# USBPHY register map
Vendor: Texas Instruments
Peripheral module from a debugger description file (folder omap4460).
Registers are 32-bit, access per field, reset 0x0 unless marked. A register's access mark holds for its fields unless they carry their own. Offsets are as the file gives them; lines under a group give offsets from that group; [hi:lo] are bit positions; {n}, {i} and the like mark numbered series; 'fields as' and 'values as' point back to an identical list; <NAME> marks a mode.

## USBPHY
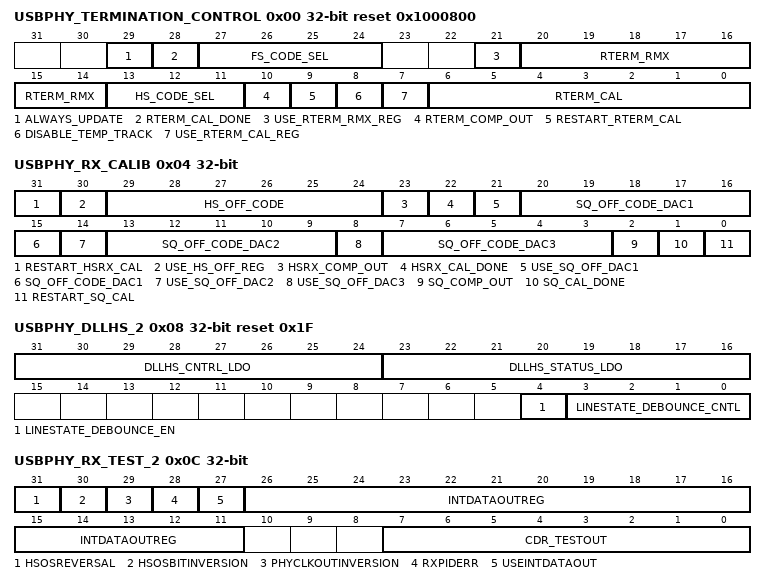
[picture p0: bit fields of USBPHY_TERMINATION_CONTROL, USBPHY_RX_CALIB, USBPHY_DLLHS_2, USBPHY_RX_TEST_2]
0x00 USBPHY_TERMINATION_CONTROL reset 0x1000800 — Contains bits related to control of terminations in USBPHY
  [29] ALWAYS_UPDATE rw — When set to 1, the calibration code is updated immediately after a code computation without waiting for idle periods.
  [28] RTERM_CAL_DONE ro — Rterm calibration is done. First time cal is done this bit gets set and gets reset at a restart cal. Read value is valid only if VDDLDO is on.
  [27:24] FS_CODE_SEL rw — FS Code selection control
  [21] USE_RTERM_RMX_REG rw — Override termination resistor trim code with RTERM_RMX from this register
  [20:14] RTERM_RMX rw — When read, this field returns the current Termination resistor trim code. Read value is valid only if VDDLDO is on. The value written to this field is used as Termination resistor trim code if bit 21 is set to 1
  [13:11] HS_CODE_SEL rw — HS Code selection control. A higher positive value (for example, +3 -- 011) reduces the termination resistance and improves the vertical eye opening.HS_CODE_SEL Offset Value Termination Calibrated Value . 000 0 ~1.5% . 001 +1 (default) 0% . 010 +2 ~–1.5% . 011 +3 ~–3% . 100 –1 3% . 101 –2 4.5% . 110 –3 6% . 111 –4 7.5% .
  [10] RTERM_COMP_OUT ro — Master loop comparator output. Read value is valid only if VDDLDO is on.
  [9] RESTART_RTERM_CAL rw — Restart the rterm calibration. the calibration restarts on any toggle 0-1 or 1-0 on this bit.
  [8] DISABLE_TEMP_TRACK rw — Disables the temperature tracking function of the termination calibration
  [7] USE_RTERM_CAL_REG rw — When 1, the rterm cal code is overridden by values in RTERM_CAL
  [6:0] RTERM_CAL rw — When read this field returns the current rterm calibration code. Read value is valid only if VDDLDO is on. The value written to this filed is used as rterm calibration code if the bit USE_RTERM_CAL_REG is 1.
0x04 USBPHY_RX_CALIB — Contains bits related to RX calibration
  [31] RESTART_HSRX_CAL rw — Restart the HSRX calibration state machine when this bit goes from 0 to 1.
  [30] USE_HS_OFF_REG rw — Override HS offset correction with HS_OFF_CODE when set to 1
  [29:24] HS_OFF_CODE rw — HS offset code, this code is forced when bit 30 is 1. Code is updated from calibration logic when bit 30 = 0.
  [23] HSRX_COMP_OUT ro — The output of the HSRX comparator. Read value is valid only if VDDLDO is on.
  [22] HSRX_CAL_DONE ro — Signal that indicates that the HSRX calibration is done. This gets reset at every restart. Read value is valid only if VDDLDO is on.
  [21] USE_SQ_OFF_DAC1 rw — Override Squelch offset DAC1 code when '1'
  [20:15] SQ_OFF_CODE_DAC1 rw — When read returns current Sq offset code for DAC1, if VDDLDO is on. When written this is used as Sq offset code for DAC1 when USE_SQ_OFF_DAC1 = 1
  [14] USE_SQ_OFF_DAC2 rw — Override Squelch offset DAC2 code when '1'
  [13:9] SQ_OFF_CODE_DAC2 rw — When read returns current Sq offset code for DAC2, if VDDLDO is on. When written this is used as Sq offset code for DAC2 when USE_SQ_OFF_DAC2 = 1
  [8] USE_SQ_OFF_DAC3 rw — Override Squelch offset DAC3 code when 1
  [7:3] SQ_OFF_CODE_DAC3 rw — When read returns current Sq offset code for DAC3, if VDDLDO is on. When written this is used as Sq offset code for DAC3 when USE_SQ_OFF_DAC3 = 1
  [2] SQ_COMP_OUT ro — Sq comp output.Read value is valid only if VDDLDO is on.
  [1] SQ_CAL_DONE ro — Sq calibration is done when this bit = 1. See RESTART_SQ_CAL for more description. Read value is valid only if VDDLDO is on.
  [0] RESTART_SQ_CAL rw — The squelch calibration continuously goes through restart cycles when this bit is 1.
0x08 USBPHY_DLLHS_2 reset 0x1F — Second DLLHS control register. Bits 4:0 are unrelated to the DLLHS and are linestate filter settings.
  [31:24] DLLHS_CNTRL_LDO rw
  [23:16] DLLHS_STATUS_LDO ro
  [4] LINESTATE_DEBOUNCE_EN rw — Enables the linestate debounce filter
  [3:0] LINESTATE_DEBOUNCE_CNTL rw — Used for control of the linestate debounce filter when going from syncronous to async linestate.
0x0C USBPHY_RX_TEST_2 — Second receiver test register
  [31] HSOSREVERSAL rw — Swaps the dataout from HSOS
  [30] HSOSBITINVERSION rw — Inverts the HSOS bits
  [29] PHYCLKOUTINVERSION rw — This inverts the phase for the PHYCLKOUT
  [28] RXPIDERR ro — Flags if the RX data packet has PID error. NOT IMPLEMENTED.
  [27] USEINTDATAOUT rw — This will bypass the analog and will send data packet to controller incase of receiver (Faking the receive data). data used will be INTDATAOUTREG
  [26:11] INTDATAOUTREG rw — This register will be loaded through OCP and this data will be given to the controller if USEINTDATAOUT is set to 1
  [7:0] CDR_TESTOUT ro — CDR debug bits. Read value is valid only if VDDLDO is on.
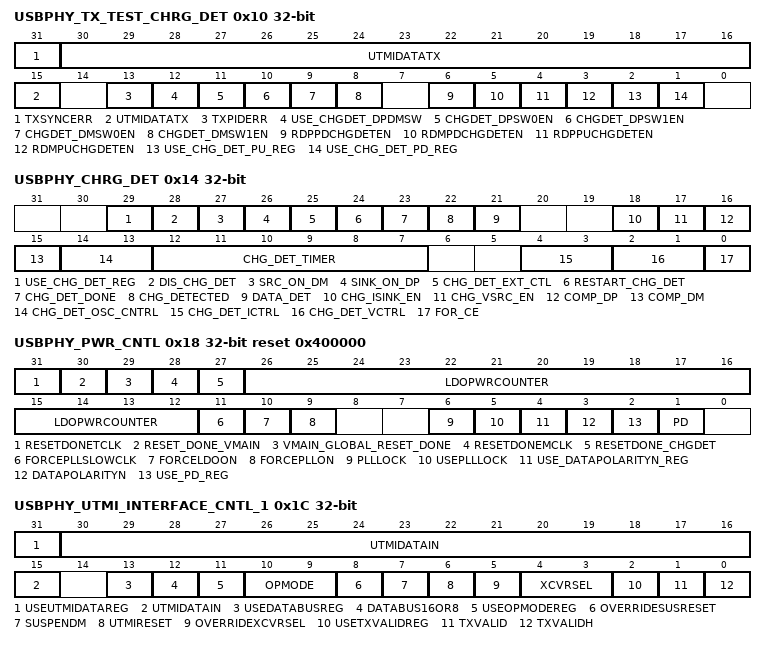
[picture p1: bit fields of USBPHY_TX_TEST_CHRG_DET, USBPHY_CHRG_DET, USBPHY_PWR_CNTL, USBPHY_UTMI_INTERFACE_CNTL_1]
0x10 USBPHY_TX_TEST_CHRG_DET — TX test register and also charger detect register
  [31] TXSYNCERR ro — Sync error on TX data. NOT IMPLEMENTED.
  [30:15] UTMIDATATX ro — Stores Last 2 byte of transmit data coming from the controller. NOT IMPLEMENTED .
  [13] TXPIDERR ro — Flags if the TX packet has PID error. NOT IMPLEMENTED.
  [12] USE_CHGDET_DPDMSW rw — Use bits 11:8 as override bits
  [11] CHGDET_DPSW0EN rw — Overrides the same named A/D interface signal for the charger detect block
  [10] CHGDET_DPSW1EN rw — Overrides the same named A/D interface signal for the charger detect block. Read value is valid only if VCHGLDO is on.
  [9] CHGDET_DMSW0EN rw — Overrides the same named A/D interface signal for the charger detect block. Read value is valid only if VCHGLDO is on.
  [8] CHGDET_DMSW1EN rw — Overrides the same named A/D interface signal for the charger detect block..Read value is valid only if VCHGLDO is on.
  [6] RDPPDCHGDETEN rw — When set to 1 connects a 15K (+/- 30%) pulldown resistor on DP. Read value is valid only if VCHGLDO is on.
  [5] RDMPDCHGDETEN rw — When set to 1 connects a 15K (+/- 30%) pulldown resistor on DM. Read value is valid only if VCHGLDO is on.
  [4] RDPPUCHGDETEN rw — When set to 1 connects a 150K (+/- 30%) pullup resistor on DP. Read value is valid only if VCHGLDO is on.
  [3] RDMPUCHGDETEN rw — When set to 1 connects a 150K (+/- 30%) pullup resistor on DM. Read value is valid only if VCHGLDO is on.
  [2] USE_CHG_DET_PU_REG rw — Use bits 4:3 from this register
  [1] USE_CHG_DET_PD_REG rw — Use bits 6:5 from this register.
0x14 USBPHY_CHRG_DET — This is the charger detect register. This register is not used in the dead battery case.
  [29] USE_CHG_DET_REG rw — Use bits 28:24 and 18:17 from this register
  [28] DIS_CHG_DET rw — When read, returns current value of charger detect input. When USE_CHG_DET_REG = 1, the value written to this filed overrides the corresponding charger detect input.
  [27] SRC_ON_DM rw — When read, returns current value of charger detect input. When USE_CHG_DET_REG = 1, the value written to this filed overrides the corresponding charger detect input.
  [26] SINK_ON_DP rw — When read, returns current value of charger detect input. When USE_CHG_DET_REG = 1, the value written to this filed overrides the corresponding charger detect input.
  [25] CHG_DET_EXT_CTL rw — When read, returns current value of charger detect input. When USE_CHG_DET_REG = 1, the value written to this filed overrides the corresponding charger detect input.
  [24] RESTART_CHG_DET rw — Restart the charger detection protocol when this goes from 0 to 1
  [23] CHG_DET_DONE ro — Charger detect protocol has completed
  [22] CHG_DETECTED ro — Same signal as CE pin
  [21] DATA_DET ro — Output of the data det comparator
  [18] CHG_ISINK_EN rw — When read, returns current value of charger detect input. When USE_CHG_DET_REG = 1, the value written to this filed overrides the corresponding charger detect input.
  [17] CHG_VSRC_EN rw — When read, returns current value of charger detect input. When USE_CHG_DET_REG = 1, the value written to this filed overrides the corresponding charger detect input.
  [16] COMP_DP ro — Comparator on the DP line value
  [15] COMP_DM ro — Comparator on the DM line value
  [14:13] CHG_DET_OSC_CNTRL rw — Charger detect osc control
  [12:7] CHG_DET_TIMER rw — Charger detect timer control.
  [4:3] CHG_DET_ICTRL rw — Charger detect current control
  [2:1] CHG_DET_VCTRL rw — Charger detect voltage buffer control
  [0] FOR_CE rw — Force CE = 1 when this bit is set
0x18 USBPHY_PWR_CNTL reset 0x400000 — Includes all the power control bits
  [31] RESETDONETCLK ro — Goes high when the RESET is synchronized to TCLK
  [30] RESET_DONE_VMAIN ro — Goes high when LDO domain is up, PLL LOCK is available, and utmi_reset is deasserted.
  [29] VMAIN_GLOBAL_RESET_DONE ro — Goes high when LDO domain is up and PLL LOCK is available.
  [28] RESETDONEMCLK ro — Goes high when the RESET is synchronized to MCLK
  [27] RESETDONE_CHGDET ro — Goes high when the RESET is synchronized to charger detect oscillator clock domain
  [26:12] LDOPWRCOUNTER rw — This is the value of the counter used for LDO power up. RESET to default.
  [11] FORCEPLLSLOWCLK rw — Forces the PLL to the slow clk mode
  [10] FORCELDOON rw — Forces the LDO to be ON.
  [9] FORCEPLLON rw — Forces the PLL to be ON.
  [6] PLLLOCK ro — Lock signal from the PLL
  [5] USEPLLLOCK rw — This signal is used to indicate to the Phy, not to do any clock related activity until PLLLOCK = 1.This is not the default option. 0 - do not use PLLLOCK. 1 - use PLLLOCK as a clock gate.
  [4] USE_DATAPOLARITYN_REG rw — 1 - use bit 3 as override for the DATAPOLARITYN signal.
  [3] DATAPOLARITYN rw — Override value of datapolarityn
  [2] USE_PD_REG rw — Use bit 1 from this register as PD override when set to 1
  [1] PD rw — Override value for PD
0x1C USBPHY_UTMI_INTERFACE_CNTL_1 rw — register to override UTMI interface control pins.
  [31] USEUTMIDATAREG — Use datain from UTMI interface register
  [30:15] UTMIDATAIN — Override value for the UTMIDATAIN
  [13] USEDATABUSREG — When set to 1 use bit 12 from register instead of interface
  [12] DATABUS16OR8 — Override value for UTMI signal DATABUS16OR8
  [11] USEOPMODEREG — When set to 1 use bits 10:9 from register instead of interface
  [10:9] OPMODE — Override value for UTMI signal OPMODE[1:0]
  [8] OVERRIDESUSRESET — Override the suspend and reset values. Use bits 6 and 7
  [7] SUSPENDM — Override value for UTMI signal SUSPENDM
  [6] UTMIRESET — Override value for UTMI signal UTMIRESET
  [5] OVERRIDEXCVRSEL — When set to 1 use bits 4:3 from register instead of interface
  [4:3] XCVRSEL — Override value for UTMI signal XCVRSEL[1:0]
  [2] USETXVALIDREG — When set to 1 use bits 1:0 from register instead of interface
  [1] TXVALID — Override value for UTMI signal TXVALID
  [0] TXVALIDH — Override value for UTMI signal TXVALIDH
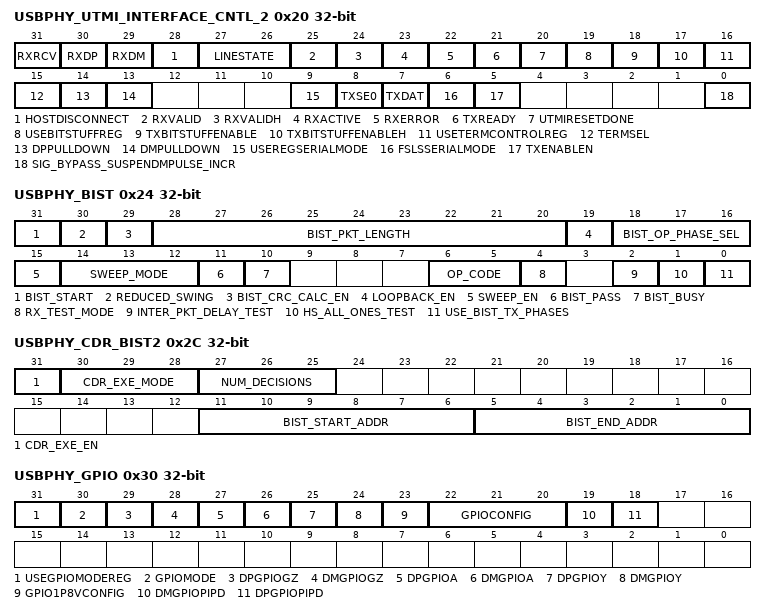
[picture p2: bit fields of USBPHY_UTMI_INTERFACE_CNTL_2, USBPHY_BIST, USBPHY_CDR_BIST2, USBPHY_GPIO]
0x20 USBPHY_UTMI_INTERFACE_CNTL_2 — UTMI interface override and observe register 2
  [31] RXRCV ro — Read for UTMI signal. Read value is valid only if VDDLDO is on. Read value is valid only if VDDLDO is on.
  [30] RXDP ro — Read for UTMI signal. Read value is valid only if VDDLDO is on.
  [29] RXDM ro — Read for UTMI signal. Read value is valid only if VDDLDO is on.
  [28] HOSTDISCONNECT ro — Read for UTMI signal. Read value is valid only if VDDLDO is on.
  [27:26] LINESTATE ro — Read for UTMI signal. Read value is valid only if VDDLDO is on.
  [25] RXVALID ro — Read for UTMI signal. Read value is valid only if VDDLDO is on.
  [24] RXVALIDH ro — Read for UTMI signal. Read value is valid only if VDDLDO is on.
  [23] RXACTIVE ro — Read for UTMI signal. Read value is valid only if VDDLDO is on.
  [22] RXERROR ro — Read for UTMI signal. Read value is valid only if VDDLDO is on.
  [21] TXREADY ro — Read for UTMI signal. Read value is valid only if VDDLDO is on.
  [20] UTMIRESETDONE ro — Read for UTMIRESETDONE signal
  [19] USEBITSTUFFREG rw — When set to 1 use bits 18-17 from register instead of interface
  [18] TXBITSTUFFENABLE rw — Override value for signal TXBITSTUFFENABLE
  [17] TXBITSTUFFENABLEH rw — Override value for pin TXBITSTUFFENABLE
  [16] USETERMCONTROLREG rw — When set to 1, bits 15:13 from register are used instead of interface
  [15] TERMSEL rw — Override value for signal TERMSEL
  [14] DPPULLDOWN rw — Override value for signal DPPULLDOWN
  [13] DMPULLDOWN rw — Override value for signal DMPULLDOWN
  [9] USEREGSERIALMODE rw — When set to 1 use bits 8:5 from register instead of interface
  [8] TXSE0 rw — Override value for signal TXSE0
  [7] TXDAT rw — Override value for signal TXDAT
  [6] FSLSSERIALMODE rw — Override value for signal FSLSSERIALMODE
  [5] TXENABLEN rw — Override value for signal TXENABLEN
  [0] SIG_BYPASS_SUSPENDMPULSE_INCR rw — If the suspend signal is asserted for a short time, it is pulse-extended so that the sampling logic samples it reliably.
    0=Pulse extension active; 1=Bypass pulse extension
0x24 USBPHY_BIST — COntains bits related to the built in self test of the phy
  [31] BIST_START rw — When set to 1 the BIST mode is started.
  [30] REDUCED_SWING rw — When 1 the TX swing is reduced in BIST mode
  [29] BIST_CRC_CALC_EN rw — Enables CRC calculation during BIST when set to 1
  [28:20] BIST_PKT_LENGTH rw — Address for which BIST to select
  [19] LOOPBACK_EN rw — Enables the loopback mode
  [18:16] BIST_OP_PHASE_SEL rw — Selects which phase to use for data transmission during BIST
  [15] SWEEP_EN rw — Enables freq sweep on CDR
  [14:12] SWEEP_MODE rw — Selects the freq sweep mode.
  [11] BIST_PASS ro — Indicates that the BIST has passed. Read value is valid only if VDDLDO is on.
  [10] BIST_BUSY ro — Indicates that BIST is running. Read value is valid only if VDDLDO is on.
  [6:5] OP_CODE rw
  [4] RX_TEST_MODE rw
  [2] INTER_PKT_DELAY_TEST rw
  [1] HS_ALL_ONES_TEST rw
  [0] USE_BIST_TX_PHASES rw — When set to 1 bits 18:16 are activated for choosing the transmitting phase.
0x28 USBPHY_BIST_CRC rw — CRC code for BIST test
  [31:0] BIST_CRC — The CRC value from the BIST.
0x2C USBPHY_CDR_BIST2 — clock data recovery register and BIST register 2
  [31] CDR_EXE_EN rw — CDR debug bits
  [30:28] CDR_EXE_MODE rw — CDR debug bits
  [27:25] NUM_DECISIONS rw — CDR debug bits
  [11:6] BIST_START_ADDR rw
  [5:0] BIST_END_ADDR rw
0x30 USBPHY_GPIO — GPIO mode configurations and reads
  [31] USEGPIOMODEREG rw — When set to 1 use bits 31:24 from this register instead of primary inputs
  [30] GPIOMODE rw — Overrides the corresponding primary input
  [29] DPGPIOGZ rw — Overrides the corresponding primary input
  [28] DMGPIOGZ rw — Overrides the corresponding primary input
  [27] DPGPIOA rw — Overrides the corresponding primary input
  [26] DMGPIOA rw — Overrides the corresponding primary input
  [25] DPGPIOY ro — The GPIO Y output is stored here
  [24] DMGPIOY ro — The GPIO Y output is stored here
  [23] GPIO1P8VCONFIG rw — Overrides the corresponding primary input
  [22:20] GPIOCONFIG rw — Used for configuring the GPIOs.
  [19] DMGPIOPIPD rw — GPIO mode DM pull-down enabled. Overrides the corresponding primary input
  [18] DPGPIOPIPD rw — GPIO mode DP pull-down enabled. Overrides the corresponding primary input.
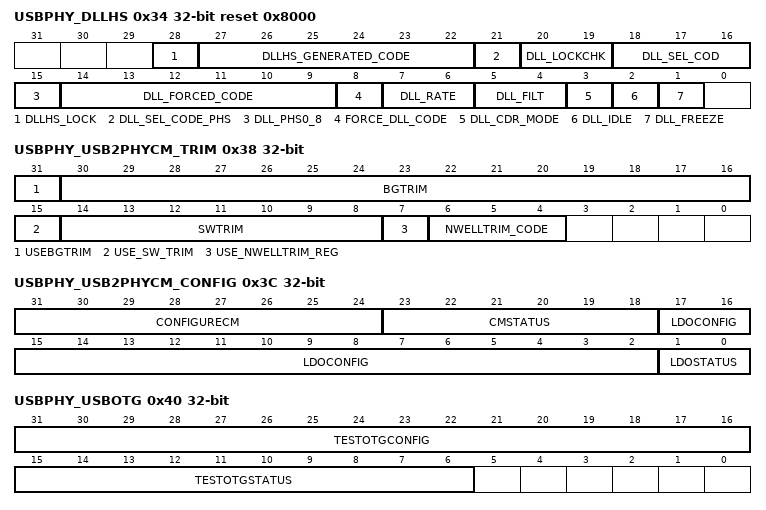
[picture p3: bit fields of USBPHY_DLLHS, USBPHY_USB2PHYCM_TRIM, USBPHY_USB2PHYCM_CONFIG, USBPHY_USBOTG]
0x34 USBPHY_DLLHS reset 0x8000 — Bits for control and debug of the DLL inside the USBPHY
  [28] DLLHS_LOCK ro — Read the AFE output by this name
  [27:22] DLLHS_GENERATED_CODE ro — Read the AFE output by this name.Read value is valid only if VDDLDO is on.
  [21] DLL_SEL_CODE_PHS rw — Connect to DLLHS_TEST_LDO[0] on AFE interface.
  [20:19] DLL_LOCKCHK rw — Connect to DLLHS_TEST_LDO[2:1] on AFE interface.
  [18:16] DLL_SEL_COD rw — Connect to DLLHS_TEST_LDO[5:3] on AFE interface.
  [15] DLL_PHS0_8 rw — Connect to DLLHS_TEST_LDO[6] on AFE interface.
  [14:9] DLL_FORCED_CODE rw — Connect to the pin of this name on AFE interface.
  [8] FORCE_DLL_CODE rw — Connect to DLLHS_TEST_LDO[11] on AFE interface.
  [7:6] DLL_RATE rw — Connect to DLLHS_TEST_LDO[8:7] on AFE interface.
  [5:4] DLL_FILT rw — Connect to DLLHS_TEST_LDO[10:9] on AFE interface.
  [3] DLL_CDR_MODE rw — Connect to the pin of this name on AFE interface.
  [2] DLL_IDLE rw — Connect to DLLHS_TEST_LDO[12] on AFE interface.
  [1] DLL_FREEZE rw — Connect to DLLHS_TEST_LDO[13] on AFE interface.
0x38 USBPHY_USB2PHYCM_TRIM rw — Contains trim bit overrides for the USBPHYCM
  [31] USEBGTRIM — When set to 1 bits 30:16 are used as the trim value for the USBPHYCM bandgap
  [30:16] BGTRIM — Override value for the BGTRIM value
  [15] USE_SW_TRIM — Use bits 14:8 to override the switch cap trim value.
  [14:8] SWTRIM — Override value for the switch cap trim value.
  [7] USE_NWELLTRIM_REG — Override NWELL resistor trim using NWELLTRIM_CODE
  [6:4] NWELLTRIM_CODE — NWELL resistor trim code.
0x3C USBPHY_USB2PHYCM_CONFIG — Configuration and status register for the USBPHYCM and LDO
  [31:24] CONFIGURECM rw — Connects to the CONFIGURECM pins.
  [23:18] CMSTATUS ro — Reads the CMSTATUS bits.
  [17:2] LDOCONFIG rw — The LDOCONFIG bit settings.
  [1:0] LDOSTATUS ro — Reads the LDOSTATUS bits.
0x40 USBPHY_USBOTG
  [31:16] TESTOTGCONFIG rw — Used to control the OTG module if used.
  [15:6] TESTOTGSTATUS ro — The OTG status bits (if OTG macro is used)
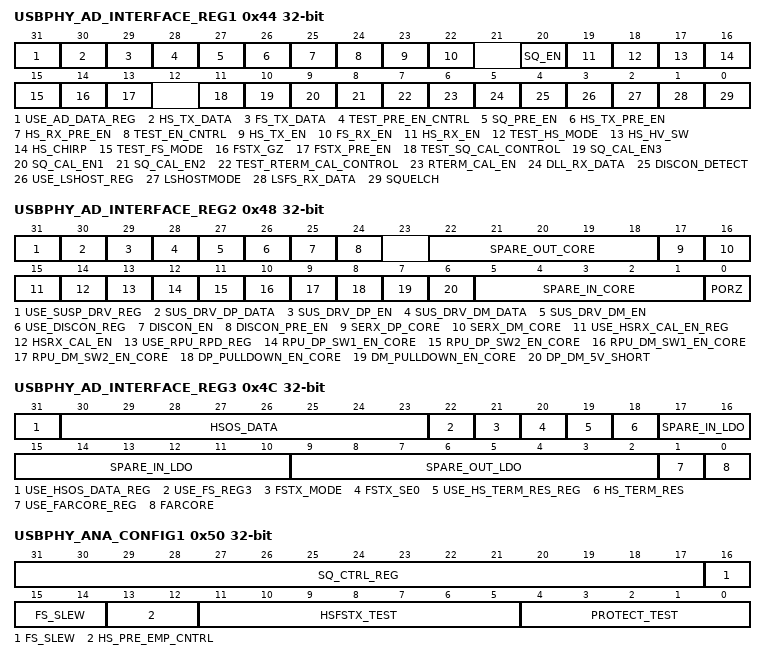
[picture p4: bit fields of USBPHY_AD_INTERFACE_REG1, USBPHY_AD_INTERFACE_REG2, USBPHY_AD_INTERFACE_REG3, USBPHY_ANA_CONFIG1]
0x44 USBPHY_AD_INTERFACE_REG1 — All bits (unless defined) are bypass bits for internal analog to digital interface pins with the same name. All the bits of this register, except the over-ride bits return a '0' on read, if VDDLDO is off.
  [31] USE_AD_DATA_REG rw — Override for bits 30:29
  [30] HS_TX_DATA rw
  [29] FS_TX_DATA rw
  [28] TEST_PRE_EN_CNTRL rw — Override for bits 27:25
  [27] SQ_PRE_EN rw
  [26] HS_TX_PRE_EN rw
  [25] HS_RX_PRE_EN rw
  [24] TEST_EN_CNTRL rw — Override for bits 23:19
  [23] HS_TX_EN rw
  [22] FS_RX_EN rw
  [20] SQ_EN rw
  [19] HS_RX_EN rw
  [18] TEST_HS_MODE rw — Override for bits 17:16
  [17] HS_HV_SW rw
  [16] HS_CHIRP rw
  [15] TEST_FS_MODE rw — Override for bits 14:12
  [14] FSTX_GZ rw
  [13] FSTX_PRE_EN rw
  [11] TEST_SQ_CAL_CONTROL rw — Override for bits 10:8
  [10] SQ_CAL_EN3 rw
  [9] SQ_CAL_EN1 rw
  [8] SQ_CAL_EN2 rw
  [7] TEST_RTERM_CAL_CONTROL rw — Override for bits 6
  [6] RTERM_CAL_EN rw
  [5] DLL_RX_DATA ro
  [4] DISCON_DETECT ro
  [3] USE_LSHOST_REG rw — Use bit 2 for this reg
  [2] LSHOSTMODE rw
  [1] LSFS_RX_DATA ro
  [0] SQUELCH ro
0x48 USBPHY_AD_INTERFACE_REG2 — All bits (unless defined) are bypass bits for internal analog to digital interface pins with the same name. All the bits of this register, except the override bits return a '0' on read, if VDDLDO is off.
  [31] USE_SUSP_DRV_REG rw — Use bits 30:27 from this register as overrides
  [30] SUS_DRV_DP_DATA rw
  [29] SUS_DRV_DP_EN rw
  [28] SUS_DRV_DM_DATA rw
  [27] SUS_DRV_DM_EN rw
  [26] USE_DISCON_REG rw — Use bits 25:24 from this register as override
  [25] DISCON_EN rw
  [24] DISCON_PRE_EN rw
  [22:18] SPARE_OUT_CORE ro
  [17] SERX_DP_CORE ro
  [16] SERX_DM_CORE ro
  [15] USE_HSRX_CAL_EN_REG rw — Use bit 14 from this register as override
  [14] HSRX_CAL_EN rw
  [13] USE_RPU_RPD_REG rw — Use override from bits 12:7
  [12] RPU_DP_SW1_EN_CORE rw
  [11] RPU_DP_SW2_EN_CORE rw
  [10] RPU_DM_SW1_EN_CORE rw
  [9] RPU_DM_SW2_EN_CORE rw
  [8] DP_PULLDOWN_EN_CORE rw
  [7] DM_PULLDOWN_EN_CORE rw
  [6] DP_DM_5V_SHORT ro
  [5:1] SPARE_IN_CORE rw
  [0] PORZ ro — Read only bit - the PORZ generated from the digital registered on the A-D interface.
0x4C USBPHY_AD_INTERFACE_REG3 — All bits (unless defined) are bypass bits for internal analog to digital interface pins with the same name. All the bits of this register, except the override bits return a '0' on read, if VDDLDO is off.
  [31] USE_HSOS_DATA_REG rw — Use bits 30:23 in this register as bypass bits
  [30:23] HSOS_DATA rw
  [22] USE_FS_REG3 rw — Use bits 21:20 as bypass bits
  [21] FSTX_MODE rw
  [20] FSTX_SE0 rw
  [19] USE_HS_TERM_RES_REG rw — Use bit 18 as override bit
  [18] HS_TERM_RES rw
  [17:10] SPARE_IN_LDO rw
  [9:2] SPARE_OUT_LDO ro
  [1] USE_FARCORE_REG rw — Use bit 0 from this register as bypass
  [0] FARCORE rw
0x50 USBPHY_ANA_CONFIG1 rw — Used to configure and debug the analog blocks.
  [31:17] SQ_CTRL_REG, [16:14] FS_SLEW, [13:12] HS_PRE_EMP_CNTRL, [11:5] HSFSTX_TEST, [4:0] PROTECT_TEST
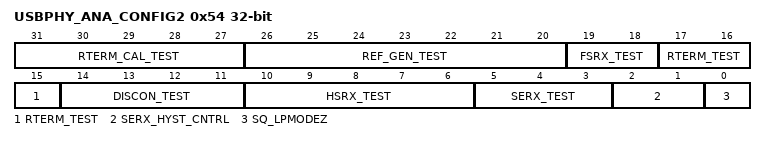
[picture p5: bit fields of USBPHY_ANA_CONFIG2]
0x54 USBPHY_ANA_CONFIG2 rw — Used to configure and debug the analog blocks.
  [31:27] RTERM_CAL_TEST
  [26:20] REF_GEN_TEST — NOT IMPLEMENTED
  [19:18] FSRX_TEST
  [17:15] RTERM_TEST — 0x0 is default 0x3 decreases the termination impedance by 2 to 3% (can be used to get 1 to 1.5% better eye vertical opening)
  [14:11] DISCON_TEST
  [10:6] HSRX_TEST
  [5:3] SERX_TEST
  [2:1] SERX_HYST_CNTRL
  [0] SQ_LPMODEZ
